# ccm register map
Vendor: Texas Instruments
Peripheral module from a debugger description file (folder sc4ce290ncpz).
Registers are 32-bit, read-write, no defined reset value unless marked. A register's access mark holds for its fields unless they carry their own. Offsets are as the file gives them; lines under a group give offsets from that group; [hi:lo] are bit positions; {n}, {i} and the like mark numbered series; 'fields as' and 'values as' point back to an identical list; <NAME> marks a mode.

## CCM0 — EC register offsets
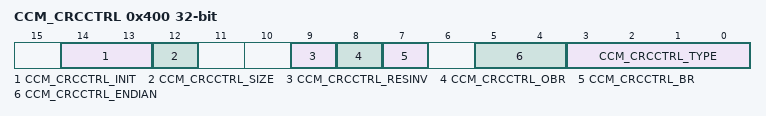
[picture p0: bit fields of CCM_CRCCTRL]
0x400 CCM_CRCCTRL — CRC Control
  [14:13] CCM_CRCCTRL_INIT — CRC Initialization
    0=CCM_CRCCTRL_INIT_SEED (Use the CRCSEED register context as the starting value); 2=Initialize to all '0s'; 3=Initialize to all '1s'
  [12] CCM_CRCCTRL_SIZE — Input Data Size
  [9] CCM_CRCCTRL_RESINV — Result Inverse Enable
  [8] CCM_CRCCTRL_OBR — Output Reverse Enable
  [7] CCM_CRCCTRL_BR — Bit reverse enable
  [5:4] CCM_CRCCTRL_ENDIAN — Endian Control
    0=CCM_CRCCTRL_ENDIAN_SBHW (Configuration unchanged. (B3, B2, B1, B0)); 1=CCM_CRCCTRL_ENDIAN_SHW (Bytes are swapped in half-words but half-words are not swapped (B2, B3, B0, B1)); 2=CCM_CRCCTRL_ENDIAN_SHWNB (Half-words are swapped but bytes are not swapped in half-word. (B1, B0, B3, B2)); 3=CCM_CRCCTRL_ENDIAN_SBSW (Bytes are swapped in half-words and half-words are swapped. (B0, B1, B2, B3))
  [3:0] CCM_CRCCTRL_TYPE — Operation Type
    0=CCM_CRCCTRL_TYPE_P8055 (Polynomial 0x8005); 1=CCM_CRCCTRL_TYPE_P1021 (Polynomial 0x1021); 2=CCM_CRCCTRL_TYPE_P4C11DB7 (Polynomial 0x4C11DB7); 3=CCM_CRCCTRL_TYPE_P1EDC6F41 (Polynomial 0x1EDC6F41); 8=CCM_CRCCTRL_TYPE_TCPCHKSUM (TCP checksum)
0x410 CCM_CRCSEED — CRC SEED/Context
  [31:0] CCM_CRCSEED_SEED — SEED/Context Value
0x414 CCM_CRCDIN — CRC Data Input
  [31:0] CCM_CRCDIN_DATAIN — Data Input
0x418 CCM_CRCRSLTPP ro — CRC Post Processing Result
  [31:0] CCM_CRCRSLTPP_RSLTPP — Post Processing Result
